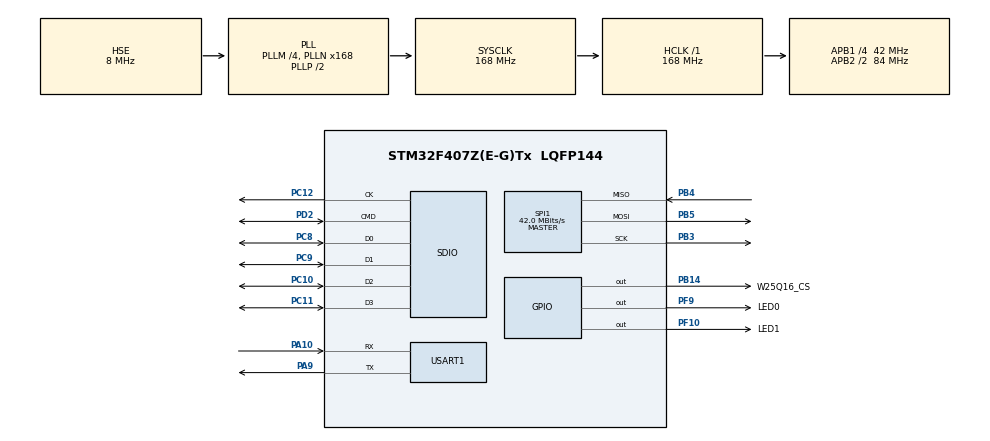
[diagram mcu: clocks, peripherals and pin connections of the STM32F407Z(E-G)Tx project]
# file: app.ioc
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FATFS._CODE_PAGE=936
FATFS._MAX_SS=4096
FATFS._MIN_SS=512
FATFS._MULTI_PARTITION=1
FATFS._USE_LFN=3
MBEDTLS.MBEDTLS_HAVE_TIME=1
MBEDTLS.MBEDTLS_NO_PLATFORM_ENTROPY=1
MBEDTLS.MBEDTLS_SSL_TLS_C=0
MBEDTLS.MBEDTLS_X509_USE_C=0
Mcu.Family=STM32F4
Mcu.Name=STM32F407Z(E-G)Tx
Mcu.Package=LQFP144
NVIC.PriorityGroup=NVIC_PRIORITYGROUP_4
NVIC.USART1_IRQn=true\:0\:0\:false\:false\:true\:true\:true
PA10.Mode=Asynchronous
PA10.Signal=USART1_RX
PA9.Mode=Asynchronous
PA9.Signal=USART1_TX
PB14.GPIO_Label=W25Q16_CS
PB14.GPIO_PuPd=GPIO_PULLUP
PB14.GPIO_Speed=GPIO_SPEED_FREQ_VERY_HIGH
PB14.PinState=GPIO_PIN_SET
PB14.Signal=GPIO_Output
PB3.Mode=Full_Duplex_Master
PB3.Signal=SPI1_SCK
PB4.Mode=Full_Duplex_Master
PB4.Signal=SPI1_MISO
PB5.Mode=Full_Duplex_Master
PB5.Signal=SPI1_MOSI
PC10.Mode=SD_4_bits_Wide_bus
PC10.Signal=SDIO_D2
PC11.Mode=SD_4_bits_Wide_bus
PC11.Signal=SDIO_D3
PC12.Mode=SD_4_bits_Wide_bus
PC12.Signal=SDIO_CK
PC8.Mode=SD_4_bits_Wide_bus
PC8.Signal=SDIO_D0
PC9.Mode=SD_4_bits_Wide_bus
PC9.Signal=SDIO_D1
PD2.Mode=SD_4_bits_Wide_bus
PD2.Signal=SDIO_CMD
PF10.GPIO_Label=LED1
PF10.GPIO_PuPd=GPIO_PULLUP
PF10.GPIO_Speed=GPIO_SPEED_FREQ_MEDIUM
PF10.PinState=GPIO_PIN_SET
PF10.Signal=GPIO_Output
PF9.GPIO_Label=LED0
PF9.GPIO_ModeDefaultOutputPP=GPIO_MODE_OUTPUT_PP
PF9.GPIO_PuPd=GPIO_PULLUP
PF9.GPIO_Speed=GPIO_SPEED_FREQ_MEDIUM
PF9.PinState=GPIO_PIN_SET
PF9.Signal=GPIO_Output
PH0-OSC_IN.Mode=HSE-External-Oscillator
PH0-OSC_IN.Signal=RCC_OSC_IN
PH1-OSC_OUT.Mode=HSE-External-Oscillator
PH1-OSC_OUT.Signal=RCC_OSC_OUT
ProjectManager.HeapSize=0x1000
ProjectManager.StackSize=0x400
ProjectManager.TargetToolchain=MDK-ARM V5
RCC.48MHZClocksFreq_Value=48000000
RCC.AHBFreq_Value=168000000
RCC.APB1CLKDivider=RCC_HCLK_DIV4
RCC.APB1Freq_Value=42000000
RCC.APB1TimFreq_Value=84000000
RCC.APB2CLKDivider=RCC_HCLK_DIV2
RCC.APB2Freq_Value=84000000
RCC.APB2TimFreq_Value=168000000
RCC.CortexFreq_Value=168000000
RCC.HCLKFreq_Value=168000000
RCC.HSE_VALUE=8000000
RCC.HSI_VALUE=16000000
RCC.LSE_VALUE=32768
RCC.PLLM=4
RCC.PLLN=168
RCC.PLLQ=7
RCC.PLLSourceVirtual=RCC_PLLSOURCE_HSE
RCC.SYSCLKFreq_VALUE=168000000
RCC.SYSCLKSource=RCC_SYSCLKSOURCE_PLLCLK
RCC.VCOOutputFreq_Value=336000000
SPI1.BaudRatePrescaler=SPI_BAUDRATEPRESCALER_2
SPI1.CLKPhase=SPI_PHASE_2EDGE
SPI1.CLKPolarity=SPI_POLARITY_HIGH
SPI1.CalculateBaudRate=42.0 MBits/s
SPI1.Direction=SPI_DIRECTION_2LINES
SPI1.Mode=SPI_MODE_MASTER
SPI1.VirtualType=VM_MASTER
USART1.VirtualMode=VM_ASYNC
VP_FATFS_VS_Generic.Mode=User_defined
VP_FATFS_VS_SDIO.Mode=SDIO
VP_MBEDTLS_VS_MBEDTLS.Mode=Enabled
board=custom

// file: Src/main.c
/**
  ******************************************************************************
  * @file           : main.c
  * @brief          : Main program body
  ******************************************************************************
  * This notice applies to any and all portions of this file
  * that are not between comment pairs USER CODE BEGIN and
  * USER CODE END. Other portions of this file, whether
  * inserted by the user or by software development tools
  * are owned by their respective copyright owners.
  *
  * Copyright (c) 2019 STMicroelectronics International N.V.
  * All rights reserved.
  *
  * Redistribution and use in source and binary forms, with or without
  * modification, are permitted, provided that the following conditions are met:
  *
  * 1. Redistribution of source code must retain the above copyright notice,
  *    this list of conditions and the following disclaimer.
  * 2. Redistributions in binary form must reproduce the above copyright notice,
  *    this list of conditions and the following disclaimer in the documentation
  *    and/or other materials provided with the distribution.
  * 3. Neither the name of STMicroelectronics nor the names of other
  *    contributors to this software may be used to endorse or promote products
  *    derived from this software without specific written permission.
  * 4. This software, including modifications and/or derivative works of this
  *    software, must execute solely and exclusively on microcontroller or
  *    microprocessor devices manufactured by or for STMicroelectronics.
  * 5. Redistribution and use of this software other than as permitted under
  *    this license is void and will automatically terminate your rights under
  *    this license.
  *
  * THIS SOFTWARE IS PROVIDED BY STMICROELECTRONICS AND CONTRIBUTORS "AS IS"
  * AND ANY EXPRESS, IMPLIED OR STATUTORY WARRANTIES, INCLUDING, BUT NOT
  * LIMITED TO, THE IMPLIED WARRANTIES OF MERCHANTABILITY, FITNESS FOR A
  * PARTICULAR PURPOSE AND NON-INFRINGEMENT OF THIRD PARTY INTELLECTUAL PROPERTY
  * RIGHTS ARE DISCLAIMED TO THE FULLEST EXTENT PERMITTED BY LAW. IN NO EVENT
  * SHALL STMICROELECTRONICS OR CONTRIBUTORS BE LIABLE FOR ANY DIRECT, INDIRECT,
  * INCIDENTAL, SPECIAL, EXEMPLARY, OR CONSEQUENTIAL DAMAGES (INCLUDING, BUT NOT
  * LIMITED TO, PROCUREMENT OF SUBSTITUTE GOODS OR SERVICES; LOSS OF USE, DATA,
  * OR PROFITS; OR BUSINESS INTERRUPTION) HOWEVER CAUSED AND ON ANY THEORY OF
  * LIABILITY, WHETHER IN CONTRACT, STRICT LIABILITY, OR TORT (INCLUDING
  * NEGLIGENCE OR OTHERWISE) ARISING IN ANY WAY OUT OF THE USE OF THIS SOFTWARE,
  * EVEN IF ADVISED OF THE POSSIBILITY OF SUCH DAMAGE.
  *
  ******************************************************************************
  */
#include "main.h"
#include "stm32f4xx_hal.h"
#include "fatfs.h"
#include "mbedtls.h"
#include "sdio.h"
#include "spi.h"
#include "usart.h"
#include "gpio.h"

/* USER CODE BEGIN PV */
/* Private variables ---------------------------------------------------------*/

/* USER CODE END PV */

void SystemClock_Config(void);

/* USER CODE BEGIN PFP */
/* Private function prototypes -----------------------------------------------*/

/* USER CODE END PFP */

/* USER CODE BEGIN 0 */
FRESULT res;
uint16_t W25QXX_TYPE;
uint8_t buff[4096];
/* USER CODE END 0 */

int main(void)
{
  /* USER CODE BEGIN 1 */
  int delay_cnt = 0;
  /* USER CODE END 1 */

  /* MCU Configuration----------------------------------------------------------*/

  /* Reset of all peripherals, Initializes the Flash interface and the Systick. */
  HAL_Init();

  /* Configure the system clock */
  SystemClock_Config();

  /* Initialize all configured peripherals */
  MX_GPIO_Init();
  MX_USART1_UART_Init();
  MX_SDIO_SD_Init();
  MX_FATFS_Init();
  MX_MBEDTLS_Init();
  MX_SPI1_Init();
  /* USER CODE BEGIN 2 */
  W25QXX_TYPE = W25QXX_ReadID();
  f_mount(&SDFatFS, "1:", 1);                          //FATFS加载SD卡
  if(f_mount(&USERFatFS, "0:", 1) == FR_NO_FILESYSTEM) //FATFS加载 W25Qxx Flash
  {
      res = f_mkfs("", FM_FAT, 0, buff, 4096);         //W25Q16的扇区太少，不能格式化成FAT32
  }
  HAL_UART_Receive_IT(&huart1, &g_UART1_RxByte, 1);    //开启串口接收中断
  /* USER CODE END 2 */

  /* Infinite loop */
  while (1)
  {

  /* USER CODE BEGIN 3 */
    HAL_Delay(10);
    if(delay_cnt++ >= 50)
    {
        delay_cnt = 0;
        HAL_GPIO_TogglePin(LED0_GPIO_Port, LED0_Pin);
    }
    USART1_Poll();
  }
  /* USER CODE END 3 */

}

void SystemClock_Config(void)
{

  RCC_OscInitTypeDef RCC_OscInitStruct;
  RCC_ClkInitTypeDef RCC_ClkInitStruct;

    /**Configure the main internal regulator output voltage
    */
  __HAL_RCC_PWR_CLK_ENABLE();

  __HAL_PWR_VOLTAGESCALING_CONFIG(PWR_REGULATOR_VOLTAGE_SCALE1);

    /**Initializes the CPU, AHB and APB busses clocks
    */
  RCC_OscInitStruct.OscillatorType = RCC_OSCILLATORTYPE_HSE;
  RCC_OscInitStruct.HSEState = RCC_HSE_ON;
  RCC_OscInitStruct.PLL.PLLState = RCC_PLL_ON;
  RCC_OscInitStruct.PLL.PLLSource = RCC_PLLSOURCE_HSE;
  RCC_OscInitStruct.PLL.PLLM = 4;
  RCC_OscInitStruct.PLL.PLLN = 168;
  RCC_OscInitStruct.PLL.PLLP = RCC_PLLP_DIV2;
  RCC_OscInitStruct.PLL.PLLQ = 7;
  if (HAL_RCC_OscConfig(&RCC_OscInitStruct) != HAL_OK)
  {
    _Error_Handler(__FILE__, __LINE__);
  }

    /**Initializes the CPU, AHB and APB busses clocks
    */
  RCC_ClkInitStruct.ClockType = RCC_CLOCKTYPE_HCLK|RCC_CLOCKTYPE_SYSCLK
                              |RCC_CLOCKTYPE_PCLK1|RCC_CLOCKTYPE_PCLK2;
  RCC_ClkInitStruct.SYSCLKSource = RCC_SYSCLKSOURCE_PLLCLK;
  RCC_ClkInitStruct.AHBCLKDivider = RCC_SYSCLK_DIV1;
  RCC_ClkInitStruct.APB1CLKDivider = RCC_HCLK_DIV4;
  RCC_ClkInitStruct.APB2CLKDivider = RCC_HCLK_DIV2;

  if (HAL_RCC_ClockConfig(&RCC_ClkInitStruct, FLASH_LATENCY_5) != HAL_OK)
  {
    _Error_Handler(__FILE__, __LINE__);
  }

    /**Configure the Systick interrupt time
    */
  HAL_SYSTICK_Config(HAL_RCC_GetHCLKFreq()/1000);

    /**Configure the Systick
    */
  HAL_SYSTICK_CLKSourceConfig(SYSTICK_CLKSOURCE_HCLK);

  /* SysTick_IRQn interrupt configuration */
  HAL_NVIC_SetPriority(SysTick_IRQn, 0, 0);
}

void _Error_Handler(char *file, int line)
{
  while(1)
  {
  }
}

/************************ (C) COPYRIGHT STMicroelectronics *****END OF FILE****/
